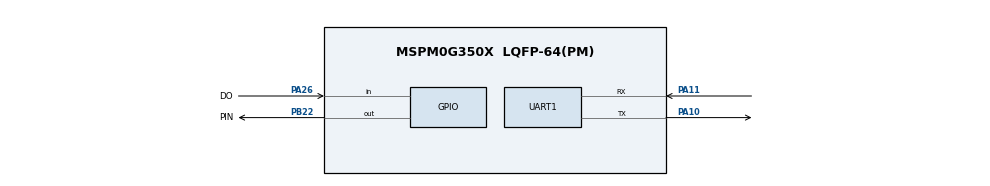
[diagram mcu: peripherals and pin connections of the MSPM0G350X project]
/**
 * @cliArgs --device "MSPM0G350X" --part "Default" --package "LQFP-64(PM)" --product "mspm0_sdk@2.02.00.05"
 * @versions {"tool":"1.21.0+3721"}
 */

/**
 * Import the modules used in this configuration.
 */
const ADC12  = scripting.addModule("/ti/driverlib/ADC12", {}, false);
const ADC121 = ADC12.addInstance();
const GPIO   = scripting.addModule("/ti/driverlib/GPIO", {}, false);
const GPIO1  = GPIO.addInstance();
const GPIO2  = GPIO.addInstance();
const SYSCTL = scripting.addModule("/ti/driverlib/SYSCTL");
const UART   = scripting.addModule("/ti/driverlib/UART", {}, false);
const UART1  = UART.addInstance();

/**
 * Write custom configuration values to the imported modules.
 */
const divider9       = system.clockTree["UDIV"];
divider9.divideValue = 2;

const mux4       = system.clockTree["EXHFMUX"];
mux4.inputSelect = "EXHFMUX_XTAL";

const mux8       = system.clockTree["HSCLKMUX"];
mux8.inputSelect = "HSCLKMUX_SYSPLL2X";

const mux12       = system.clockTree["SYSPLLMUX"];
mux12.inputSelect = "zSYSPLLMUX_HFCLK";

const pinFunction4        = system.clockTree["HFXT"];
pinFunction4.inputFreq    = 40;
pinFunction4.enable       = true;
pinFunction4.HFCLKMonitor = true;
pinFunction4.HFXTStartup  = 20;

ADC121.$name                      = "ADC12_0";
ADC121.sampClkDiv                 = "DL_ADC12_CLOCK_DIVIDE_8";
ADC121.repeatMode                 = true;
ADC121.sampleMode                 = "DL_ADC12_SAMPLING_SOURCE_MANUAL";
ADC121.adcMem0_name               = "CH0";
ADC121.powerDownMode              = "DL_ADC12_POWER_DOWN_MODE_MANUAL";
ADC121.peripheral.$assign         = "ADC0";
ADC121.peripheral.adcPin0.$assign = "PA27";
ADC121.adcPin0Config.$name        = "ti_driverlib_gpio_GPIOPinGeneric2";

const Board = scripting.addModule("/ti/driverlib/Board", {}, false);

GPIO1.$name                          = "LED";
GPIO1.associatedPins[0].$name        = "PIN";
GPIO1.associatedPins[0].ioStructure  = "SD";
GPIO1.associatedPins[0].assignedPort = "PORTB";
GPIO1.associatedPins[0].assignedPin  = "22";
GPIO1.associatedPins[0].pin.$assign  = "PB22";

GPIO2.$name                         = "GPIO";
GPIO2.port                          = "PORTA";
GPIO2.associatedPins[0].direction   = "INPUT";
GPIO2.associatedPins[0].$name       = "DO";
GPIO2.associatedPins[0].assignedPin = "26";
GPIO2.associatedPins[0].pin.$assign = "PA26";

SYSCTL.forceDefaultClkConfig = true;
SYSCTL.clockTreeEn           = true;
SYSCTL.validateClkStatus     = true;

UART1.$name                        = "UART_0";
UART1.targetBaudRate               = 115200;
UART1.peripheral.$assign           = "UART0";
UART1.peripheral.rxPin.$assign     = "PA11";
UART1.peripheral.txPin.$assign     = "PA10";
UART1.txPinConfig.$name            = "ti_driverlib_gpio_GPIOPinGeneric0";
UART1.txPinConfig.enableConfig     = true;
UART1.txPinConfig.internalResistor = "PULL_UP";
UART1.rxPinConfig.$name            = "ti_driverlib_gpio_GPIOPinGeneric1";
UART1.rxPinConfig.enableConfig     = true;
UART1.rxPinConfig.internalResistor = "PULL_UP";

/**
 * Pinmux solution for unlocked pins/peripherals. This ensures that minor changes to the automatic solver in a future
 * version of the tool will not impact the pinmux you originally saw.  These lines can be completely deleted in order to
 * re-solve from scratch.
 */
pinFunction4.peripheral.$suggestSolution           = "SYSCTL";
pinFunction4.peripheral.hfxInPin.$suggestSolution  = "PA5";
pinFunction4.peripheral.hfxOutPin.$suggestSolution = "PA6";
Board.peripheral.$suggestSolution                  = "DEBUGSS";
Board.peripheral.swclkPin.$suggestSolution         = "PA20";
Board.peripheral.swdioPin.$suggestSolution         = "PA19";
